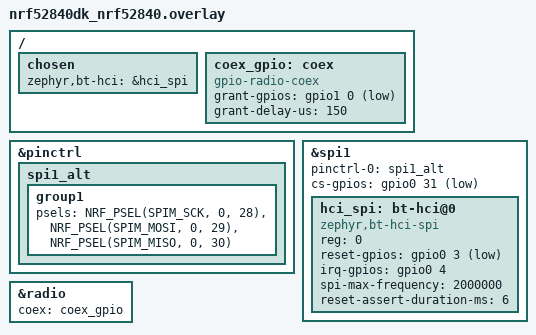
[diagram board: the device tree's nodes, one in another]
&pinctrl {
	spi1_alt: spi1_alt {
		group1 {
			psels = <NRF_PSEL(SPIM_SCK, 0, 28)>,
					<NRF_PSEL(SPIM_MOSI, 0, 29)>,
					<NRF_PSEL(SPIM_MISO, 0, 30)>;
		};
	};
};

/ {
	chosen {
		zephyr,bt-hci = &hci_spi;
	};
};

&spi1 {
	status = "okay";

	pinctrl-0 = <&spi1_alt>;
	pinctrl-names = "default";
	/delete-property/ pinctrl-1;
	cs-gpios = < &gpio0 31 GPIO_ACTIVE_LOW >;

	hci_spi: bt-hci@0 {
		compatible = "zephyr,bt-hci-spi";
		reg = <0>;
		reset-gpios = <&gpio0 3 (GPIO_ACTIVE_LOW | GPIO_PULL_UP)>;
		irq-gpios = <&gpio0 4 GPIO_ACTIVE_HIGH>;
		spi-max-frequency = <2000000>;
		reset-assert-duration-ms = <6>;
	};
};

/{
	coex_gpio: coex {
		compatible = "gpio-radio-coex";
		grant-gpios = <&gpio1 0 (GPIO_PULL_DOWN | GPIO_ACTIVE_LOW)>;
		grant-delay-us = <150>;
	};
};

&radio {
	coex = <&coex_gpio>;
};
